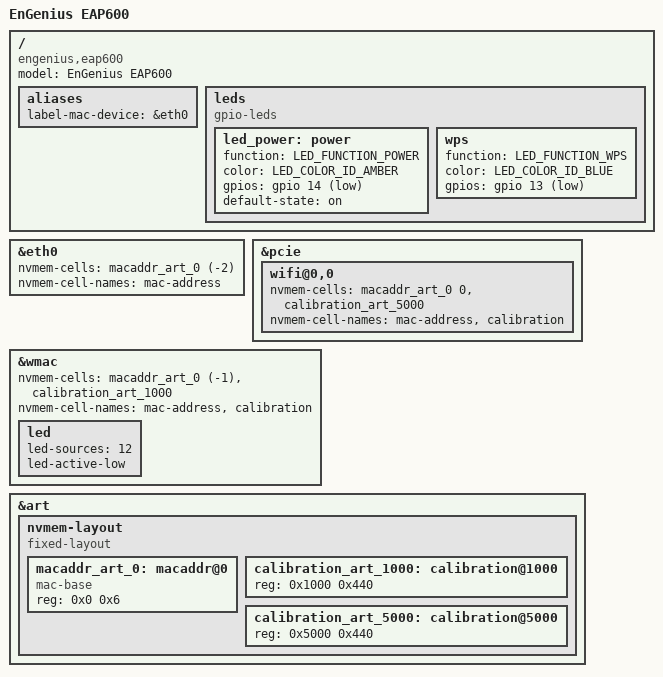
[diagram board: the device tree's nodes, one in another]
// SPDX-License-Identifier: GPL-2.0-or-later OR MIT

#include <dt-bindings/leds/common.h>

#include "ar9344_senao_ap-dual.dtsi"

/ {
	model = "EnGenius EAP600";
	compatible = "engenius,eap600", "qca,ar9344";

	aliases {
		label-mac-device = &eth0;
	};

	leds {
		compatible = "gpio-leds";

		led_power: power {
			function = LED_FUNCTION_POWER;
			color = <LED_COLOR_ID_AMBER>;
			gpios = <&gpio 14 GPIO_ACTIVE_LOW>;
			default-state = "on";
		};

		wps {
			function = LED_FUNCTION_WPS;
			color = <LED_COLOR_ID_BLUE>;
			gpios = <&gpio 13 GPIO_ACTIVE_LOW>;
		};
	};
};

&eth0 {
	nvmem-cells = <&macaddr_art_0 (-2)>;
	nvmem-cell-names = "mac-address";
};

&pcie {
	wifi@0,0 {
		nvmem-cells = <&macaddr_art_0 0>, <&calibration_art_5000>;
		nvmem-cell-names = "mac-address", "calibration";
	};
};

&wmac {
	nvmem-cells = <&macaddr_art_0 (-1)>, <&calibration_art_1000>;
	nvmem-cell-names = "mac-address", "calibration";

	led {
		led-sources = <12>;
		led-active-low;
	};
};

&art {
	nvmem-layout {
		compatible = "fixed-layout";
		#address-cells = <1>;
		#size-cells = <1>;

		macaddr_art_0: macaddr@0 {
			compatible = "mac-base";
			reg = <0x0 0x6>;
			#nvmem-cell-cells = <1>;
		};

		calibration_art_1000: calibration@1000 {
			reg = <0x1000 0x440>;
		};

		calibration_art_5000: calibration@5000 {
			reg = <0x5000 0x440>;
		};
	};
};
